# ESP32-S2 register map
Vendor: ESPRESSIF SYSTEMS (SHANGHAI) CO., LTD.; Series: ESP32 S-Series; File version: 20
CPU: Xtensa LX7 r0p0, little endian, no MPU, no FPU, 0 interrupt priority bits
Address unit: 32 bits
Registers are 32-bit, read-write, reset 0x0 unless marked. A register's access mark holds for its fields unless they carry their own. Offsets are from the block's base; [hi:lo] are bit positions; {n}, {i} and the like mark numbered series.

## SENS — SENS Peripheral
Base 0x3F408800
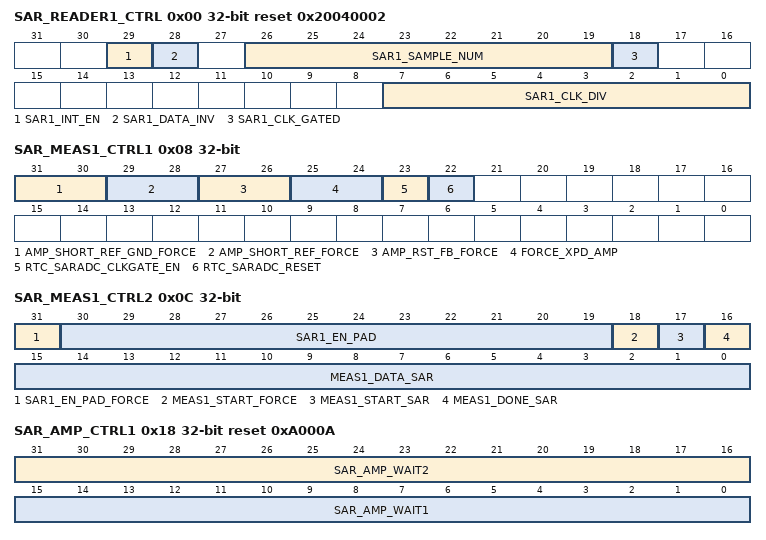
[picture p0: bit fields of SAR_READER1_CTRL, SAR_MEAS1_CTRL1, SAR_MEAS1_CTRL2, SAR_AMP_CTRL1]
0x00 SAR_READER1_CTRL reset 0x20040002 — RTC ADC1 data and sampling control
  [29] SAR1_INT_EN — Enable SAR ADC1 to send out interrupt.
  [28] SAR1_DATA_INV — Invert SAR ADC1 data.
  [26:19] SAR1_SAMPLE_NUM
  [18] SAR1_CLK_GATED
  [7:0] SAR1_CLK_DIV — Clock divider.
0x04 SAR_READER1_STATUS ro — saradc1 status for debug
  [31:0] SAR1_READER_STATUS
0x08 SAR_MEAS1_CTRL1 — Configure RTC ADC1 controller
  [31:30] AMP_SHORT_REF_GND_FORCE
  [29:28] AMP_SHORT_REF_FORCE
  [27:26] AMP_RST_FB_FORCE
  [25:24] FORCE_XPD_AMP
  [23] RTC_SARADC_CLKGATE_EN — Enable bit of SAR ADC clock gate.
  [22] RTC_SARADC_RESET — SAR ADC software reset.
0x0C SAR_MEAS1_CTRL2 access per field — Control RTC ADC1 conversion and status
  [31] SAR1_EN_PAD_FORCE rw — 1: SAR ADC1 pad enable bitmap is controlled by software. 0: SAR ADC1 pad enable bitmap is controlled by ULP coprocessor.
  [30:19] SAR1_EN_PAD rw — SAR ADC1 pad enable bitmap, active only when SENS_SAR1_EN_PAD_FORCE = 1.
  [18] MEAS1_START_FORCE rw — 1: SAR ADC1 controller (in RTC) is started by software. 0: SAR ADC1 controller is started by ULP coprocessor.
  [17] MEAS1_START_SAR rw — SAR ADC1 controller (in RTC) starts conversion, active only when SENS_MEAS1_START_FORCE = 1.
  [16] MEAS1_DONE_SAR ro — Indicate SAR ADC1 conversion is done.
  [15:0] MEAS1_DATA_SAR ro — SAR ADC1 data
0x10 SAR_MEAS1_MUX — Select the controller for SAR ADC1
  [31] SAR1_DIG_FORCE — 1: SAR ADC1 controlled by DIG ADC1 CTRL
0x14 SAR_ATTEN1 reset 0xFFFFFFFF — Configure SAR ADC1 attenuation
  [31:0] SAR1_ATTEN — 2-bit attenuation for each pad. [1:0] is used for channel 0, [3:2] is used for channel 1, etc.
0x18 SAR_AMP_CTRL1 reset 0xA000A — AMP control
  [31:16] SAR_AMP_WAIT2, [15:0] SAR_AMP_WAIT1
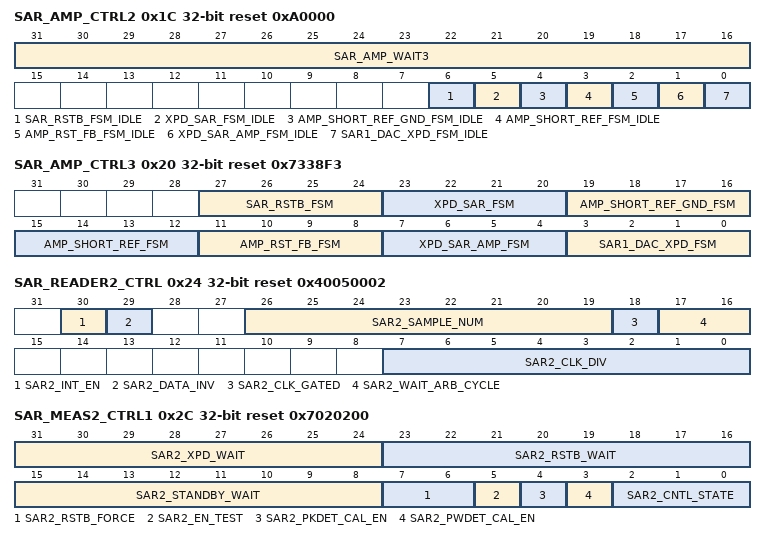
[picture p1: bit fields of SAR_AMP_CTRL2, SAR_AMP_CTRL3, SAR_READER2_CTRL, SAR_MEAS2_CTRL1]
0x1C SAR_AMP_CTRL2 reset 0xA0000 — AMP control
  [31:16] SAR_AMP_WAIT3, [6] SAR_RSTB_FSM_IDLE, [5] XPD_SAR_FSM_IDLE, [4] AMP_SHORT_REF_GND_FSM_IDLE, [3] AMP_SHORT_REF_FSM_IDLE, [2] AMP_RST_FB_FSM_IDLE, [1] XPD_SAR_AMP_FSM_IDLE, [0] SAR1_DAC_XPD_FSM_IDLE
0x20 SAR_AMP_CTRL3 reset 0x7338F3 — AMP control register
  [27:24] SAR_RSTB_FSM
  [23:20] XPD_SAR_FSM
  [19:16] AMP_SHORT_REF_GND_FSM
  [15:12] AMP_SHORT_REF_FSM
  [11:8] AMP_RST_FB_FSM
  [7:4] XPD_SAR_AMP_FSM
  [3:0] SAR1_DAC_XPD_FSM — Control of DAC. 4’b0010: disable DAC. 4’b0000: power up DAC by FSM. 4’b0011: power up DAC by software.
0x24 SAR_READER2_CTRL reset 0x40050002 — RTC ADC2 data and sampling control
  [30] SAR2_INT_EN — enable saradc2 to send out interrupt
  [29] SAR2_DATA_INV — Invert SAR ADC2 data
  [26:19] SAR2_SAMPLE_NUM
  [18] SAR2_CLK_GATED
  [17:16] SAR2_WAIT_ARB_CYCLE — wait arbit stable after sar_done
  [7:0] SAR2_CLK_DIV — clock divider
0x28 SAR_READER2_STATUS ro — saradc2 status for debug
  [31:0] SAR2_READER_STATUS
0x2C SAR_MEAS2_CTRL1 access per field reset 0x7020200 — configure rtc saradc2
  [31:24] SAR2_XPD_WAIT rw
  [23:16] SAR2_RSTB_WAIT rw
  [15:8] SAR2_STANDBY_WAIT rw
  [7:6] SAR2_RSTB_FORCE rw
  [5] SAR2_EN_TEST rw
  [4] SAR2_PKDET_CAL_EN rw — rtc control pkdet enable
  [3] SAR2_PWDET_CAL_EN rw — rtc control pwdet enable
  [2:0] SAR2_CNTL_STATE ro — saradc2_cntl_fsm
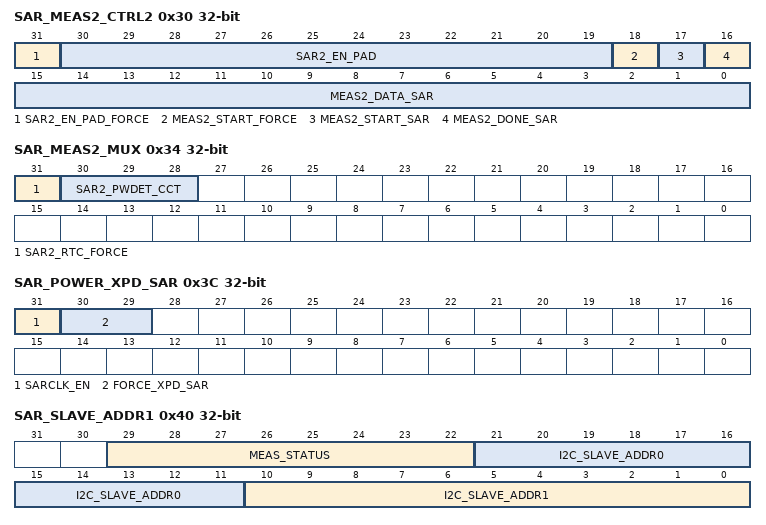
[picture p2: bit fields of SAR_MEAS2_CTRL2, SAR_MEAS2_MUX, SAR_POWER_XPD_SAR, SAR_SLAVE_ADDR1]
0x30 SAR_MEAS2_CTRL2 access per field — Control RTC ADC2 conversion and status
  [31] SAR2_EN_PAD_FORCE rw — 1: SAR ADC2 pad enable bitmap is controlled by software. 0: SAR ADC2 pad enable bitmap is controlled by ULP coprocessor.
  [30:19] SAR2_EN_PAD rw — SAR ADC2 pad enable bitmap, active only whenSENS_SAR2_EN_PAD_FORCE = 1.
  [18] MEAS2_START_FORCE rw — 1: SAR ADC2 controller (in RTC) is started by software. 0: SAR ADC2 controller is started by ULP coprocessor.
  [17] MEAS2_START_SAR rw — SAR ADC2 controller (in RTC) starts conversion, active only when SENS_MEAS2_START_FORCE = 1.
  [16] MEAS2_DONE_SAR ro — Indicate SAR ADC2 conversion is done.
  [15:0] MEAS2_DATA_SAR ro — SAR ADC2 data.
0x34 SAR_MEAS2_MUX — Select the controller for SAR ADC2
  [31] SAR2_RTC_FORCE — In sleep, force to use RTC to control ADC.
  [30:28] SAR2_PWDET_CCT — SAR2_PWDET_CCT, PA power detector capacitance tuning.
0x38 SAR_ATTEN2 reset 0xFFFFFFFF — Configure SAR ADC2 attenuation
  [31:0] SAR2_ATTEN — 2-bit attenuation for each pad. [1:0] is used for channel 0, [3:2] is used for channel 1, etc.
0x3C SAR_POWER_XPD_SAR — configure saradc’s power by sw
  [31] SARCLK_EN, [30:29] FORCE_XPD_SAR
0x40 SAR_SLAVE_ADDR1 access per field — Configure slave addresses 0-1 of RTC I2C
  [29:22] MEAS_STATUS ro
  [21:11] I2C_SLAVE_ADDR0 rw — RTC I2C slave address 0
  [10:0] I2C_SLAVE_ADDR1 rw — RTC I2C slave address 1
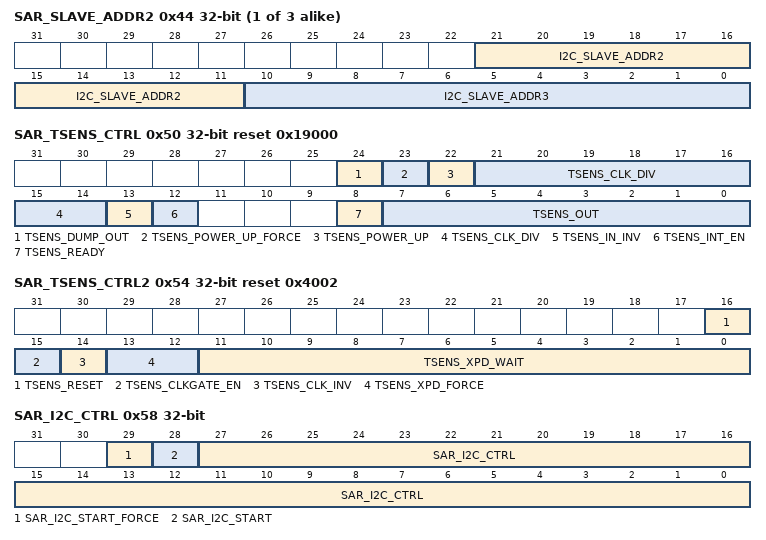
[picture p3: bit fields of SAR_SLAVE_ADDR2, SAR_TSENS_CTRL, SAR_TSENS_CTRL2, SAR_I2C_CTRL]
{0x3C+4i} SAR_SLAVE_ADDR{i} (i=2..4) — Configure slave addresses {2i-2}-{2i-1} of RTC I2C
  [21:11] I2C_SLAVE_ADDR{2i-2} — RTC I2C slave address {2i-2}
  [10:0] I2C_SLAVE_ADDR{2i-1} — RTC I2C slave address {2i-1}
0x50 SAR_TSENS_CTRL access per field reset 0x19000 — Temperature sensor data control
  [24] TSENS_DUMP_OUT rw — Temperature sensor dump out only active when SENS_TSENS_POWER_UP_FORCE = 1.
  [23] TSENS_POWER_UP_FORCE rw — 1: dump out and power up controlled by software. 0: by FSM.
  [22] TSENS_POWER_UP rw — Temperature sensor power up.
  [21:14] TSENS_CLK_DIV rw — Temperature sensor clock divider.
  [13] TSENS_IN_INV rw — Invert temperature sensor data.
  [12] TSENS_INT_EN rw — Enable temperature sensor to send out interrupt.
  [8] TSENS_READY ro — Indicate temperature sensor out ready.
  [7:0] TSENS_OUT ro — Temperature sensor data out.
0x54 SAR_TSENS_CTRL2 reset 0x4002 — Temperature sensor control
  [16] TSENS_RESET — Reset temperature sensor.
  [15] TSENS_CLKGATE_EN — Enable temperature sensor clock.
  [14] TSENS_CLK_INV
  [13:12] TSENS_XPD_FORCE
  [11:0] TSENS_XPD_WAIT
0x58 SAR_I2C_CTRL — Configure RTC I2C transmission
  [29] SAR_I2C_START_FORCE — 0: RTC I2C started by FSM. 1: RTC I2C started by software.
  [28] SAR_I2C_START — Start RTC I2C. Active only when SENS_SAR_I2C_START_FORCE = 1
  [27:0] SAR_I2C_CTRL — RTC I2C control data. Active only when SENS_SAR_I2C_START_FORCE = 1.
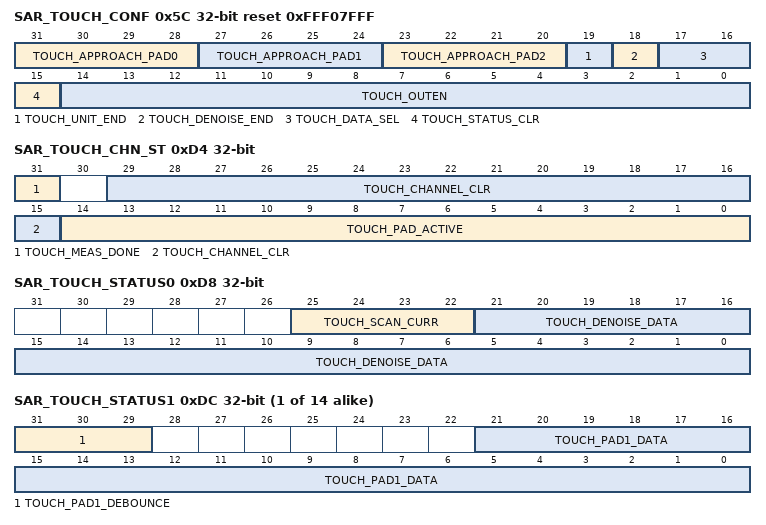
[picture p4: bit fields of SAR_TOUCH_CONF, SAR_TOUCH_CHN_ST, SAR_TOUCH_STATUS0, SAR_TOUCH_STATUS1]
0x5C SAR_TOUCH_CONF access per field reset 0xFFF07FFF — Touch sensor configuration register
  [31:28] TOUCH_APPROACH_PAD0 rw — Indicate which pad is selected as proximity pad0
  [27:24] TOUCH_APPROACH_PAD1 rw — Indicate which pad is selected as proximity pad1
  [23:20] TOUCH_APPROACH_PAD2 rw — Indicate which pad is selected as proximity pad2
  [19] TOUCH_UNIT_END ro — Indicate the completion of sampling.
  [18] TOUCH_DENOISE_END ro — Touch denoise done.
  [17:16] TOUCH_DATA_SEL rw — 0 and 1: touch_raw_data; 2: base_line; 3: touch_smooth_data.
  [15] TOUCH_STATUS_CLR wo — Clear all touch active status.
  [14:0] TOUCH_OUTEN rw — Enable touch controller output.
{0x5C+4i} SAR_TOUCH_THRES{i} (i=1..14) — Finger threshold for touch pad {i}
  [21:0] TOUCH_OUT_TH{i}
0xD4 SAR_TOUCH_CHN_ST access per field — Touch channel status register
  [31] TOUCH_MEAS_DONE ro — Signal flag that indicates one touch pad is done.
  [29:15] TOUCH_CHANNEL_CLR wo — Clear touch channel
  [14:0] TOUCH_PAD_ACTIVE ro — Touch active status
0xD8 SAR_TOUCH_STATUS0 ro — Status of touch controller
  [25:22] TOUCH_SCAN_CURR — Current pad in scan status
  [21:0] TOUCH_DENOISE_DATA — Denoise measure value from touch sensor 0.
{0xD8+4i} SAR_TOUCH_STATUS{i} ro (i=1..14) — Touch pad {i} status
  [31:29] TOUCH_PAD{i}_DEBOUNCE — Touch pad {i} debounce value.
  [21:0] TOUCH_PAD{i}_DATA — The data of touch pad {i}, depending on the setting of SENS_TOUCH_DATA_SEL.
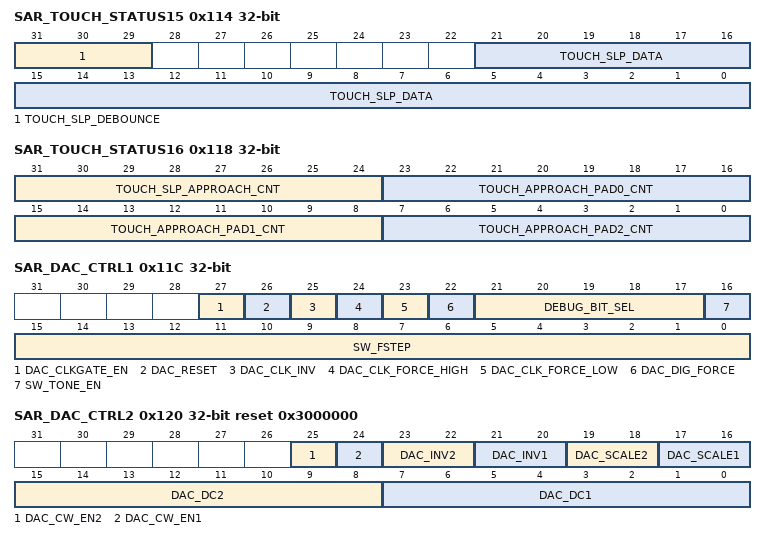
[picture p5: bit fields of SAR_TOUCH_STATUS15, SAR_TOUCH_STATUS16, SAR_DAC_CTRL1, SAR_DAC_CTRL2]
0x114 SAR_TOUCH_STATUS15 ro — Touch sleep pad status
  [31:29] TOUCH_SLP_DEBOUNCE — Touch sleep pad debouce value.
  [21:0] TOUCH_SLP_DATA — The data of touch sleep pad, depending on the setting of SENS_TOUCH_DATA_SEL.
0x118 SAR_TOUCH_STATUS16 ro — Touch approach count status
  [31:24] TOUCH_SLP_APPROACH_CNT — Count status of sleep pad in proximity mode.
  [23:16] TOUCH_APPROACH_PAD0_CNT — Count status of proximity pad 0.
  [15:8] TOUCH_APPROACH_PAD1_CNT — Count status of proximity pad 1.
  [7:0] TOUCH_APPROACH_PAD2_CNT — Count status of proximity pad 2.
0x11C SAR_DAC_CTRL1 — DAC control
  [27] DAC_CLKGATE_EN — DAC clock gate enable bit.
  [26] DAC_RESET — Reset DAC by software.
  [25] DAC_CLK_INV — 1: invert PDAC_CLK.
  [24] DAC_CLK_FORCE_HIGH — 1: force PDAC_CLK to high
  [23] DAC_CLK_FORCE_LOW — 1: force PDAC_CLK to low
  [22] DAC_DIG_FORCE — 0: DAC1 and DAC2 do not use DMA. 1: DAC1 and DAC2 use DMA.
  [21:17] DEBUG_BIT_SEL
  [16] SW_TONE_EN — 0: disable CW generator. 1: enable CW generator.
  [15:0] SW_FSTEP — Frequency step for CW generator can be used to adjust the frequency.
0x120 SAR_DAC_CTRL2 reset 0x3000000 — DAC output control
  [25] DAC_CW_EN2 — 1: select CW generator as source for PDAC2_DAC. 0: select register RT- CIO_PDAC2_DAC as source for PDAC2_DAC.
  [24] DAC_CW_EN1 — 1: select CW generator as source for PDAC1_DAC. 0: select register RT- CIO_PDAC1_DAC as source for PDAC1_DAC.
  [23:22] DAC_INV2 — Invert DAC2. 00: do not invert any bits. 01: invert all bits. 10: invert MSB. 11: invert all bits except MSB.
  [21:20] DAC_INV1 — Invert DAC1. 00: do not invert any bits. 01: invert all bits. 10: invert MSB. 11: invert all bits except MSB.
  [19:18] DAC_SCALE2 — DAC2 scaling. 00: no scale. 01: scale to 1/2. 10: scale to 1/4. 11: scale to 1/8.
  [17:16] DAC_SCALE1 — DAC1 scaling. 00: no scale. 01: scale to 1/2. 10: scale to 1/4. 11: scale to 1/8.
  [15:8] DAC_DC2 — DC offset for DAC2 CW generator.
  [7:0] DAC_DC1 — DC offset for DAC1 CW generator.
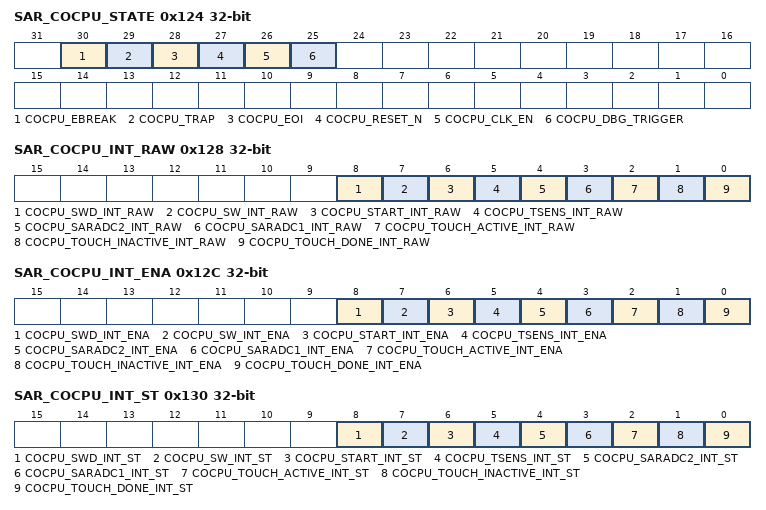
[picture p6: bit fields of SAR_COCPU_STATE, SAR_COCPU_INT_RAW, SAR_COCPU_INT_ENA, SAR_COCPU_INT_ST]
0x124 SAR_COCPU_STATE access per field — ULP-RISCV status
  [30] COCPU_EBREAK ro — Check ULP-RISCV whether in ebreak
  [29] COCPU_TRAP ro — Check ULP-RISCV whether in trap state
  [28] COCPU_EOI ro — Check ULP-RISCV whether in interrupt state
  [27] COCPU_RESET_N ro — Check ULP-RISCV whether in reset state
  [26] COCPU_CLK_EN ro — Check ULP-RISCV whether clk on
  [25] COCPU_DBG_TRIGGER wo — Trigger ULP-RISCV debug registers
0x128 SAR_COCPU_INT_RAW ro — Interrupt raw bit of ULP-RISCV
  [8] COCPU_SWD_INT_RAW — SWD_INT interrupt raw bit
  [7] COCPU_SW_INT_RAW — SW_INT interrupt raw bit
  [6] COCPU_START_INT_RAW — RISCV_START_INT interrupt raw bit
  [5] COCPU_TSENS_INT_RAW — TSENS_DONE_INT interrupt raw bit
  [4] COCPU_SARADC2_INT_RAW — SARADC2_DONE_INT interrupt raw bit
  [3] COCPU_SARADC1_INT_RAW — SARADC1_DONE_INT interrupt raw bit
  [2] COCPU_TOUCH_ACTIVE_INT_RAW — TOUCH_ACTIVE_INT interrupt raw bit
  [1] COCPU_TOUCH_INACTIVE_INT_RAW — TOUCH_INACTIVE_INT interrupt raw bit
  [0] COCPU_TOUCH_DONE_INT_RAW — TOUCH_DONE_INT interrupt raw bit
0x12C SAR_COCPU_INT_ENA — Interrupt enable bit of ULP-RISCV
  [8] COCPU_SWD_INT_ENA — SWD_INT interrupt enable bit
  [7] COCPU_SW_INT_ENA — SW_INT interrupt enable bit
  [6] COCPU_START_INT_ENA — RISCV_START_INT interrupt enable bit
  [5] COCPU_TSENS_INT_ENA — TSENS_DONE_INT interrupt enable bit
  [4] COCPU_SARADC2_INT_ENA — SARADC2_DONE_INT interrupt enable bit
  [3] COCPU_SARADC1_INT_ENA — SARADC1_DONE_INT interrupt enable bit
  [2] COCPU_TOUCH_ACTIVE_INT_ENA — TOUCH_ACTIVE_INT interrupt enable bit
  [1] COCPU_TOUCH_INACTIVE_INT_ENA — TOUCH_INACTIVE_INT interrupt enable bit
  [0] COCPU_TOUCH_DONE_INT_ENA — TOUCH_DONE_INT interrupt enable bit
0x130 SAR_COCPU_INT_ST ro — Interrupt status bit of ULP-RISCV
  [8] COCPU_SWD_INT_ST — SWD_INT interrupt status bit
  [7] COCPU_SW_INT_ST — SW_INT interrupt status bit
  [6] COCPU_START_INT_ST — RISCV_START_INT interrupt status bit
  [5] COCPU_TSENS_INT_ST — TSENS_DONE_INT interrupt status bit
  [4] COCPU_SARADC2_INT_ST — SARADC2_DONE_INT interrupt status bit
  [3] COCPU_SARADC1_INT_ST — SARADC1_DONE_INT interrupt status bit
  [2] COCPU_TOUCH_ACTIVE_INT_ST — TOUCH_ACTIVE_INT interrupt status bit
  [1] COCPU_TOUCH_INACTIVE_INT_ST — TOUCH_INACTIVE_INT interrupt status bit
  [0] COCPU_TOUCH_DONE_INT_ST — TOUCH_DONE_INT interrupt status bit
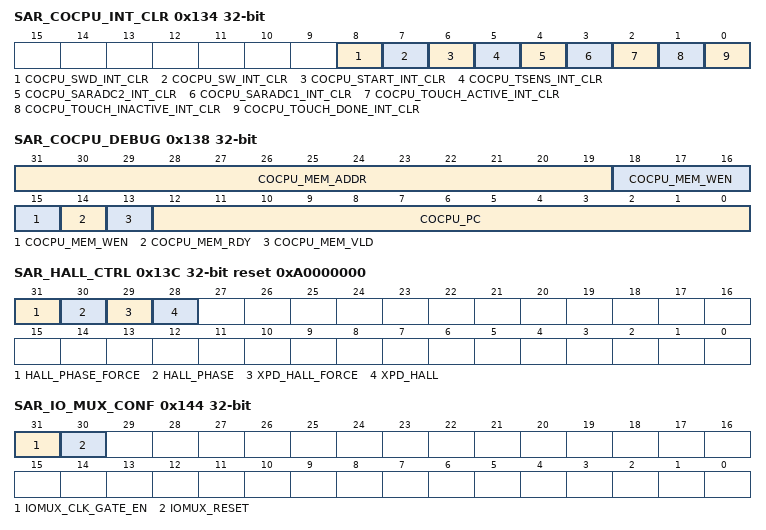
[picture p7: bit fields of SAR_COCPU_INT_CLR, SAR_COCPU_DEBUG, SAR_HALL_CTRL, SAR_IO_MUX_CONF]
0x134 SAR_COCPU_INT_CLR wo — Interrupt clear bit of ULP-RISCV
  [8] COCPU_SWD_INT_CLR — SWD_INT interrupt clear bit
  [7] COCPU_SW_INT_CLR — SW_INT interrupt clear bit
  [6] COCPU_START_INT_CLR — RISCV_START_INT interrupt clear bit
  [5] COCPU_TSENS_INT_CLR — TSENS_DONE_INT interrupt clear bit
  [4] COCPU_SARADC2_INT_CLR — SARADC2_DONE_INT interrupt clear bit
  [3] COCPU_SARADC1_INT_CLR — SARADC1_DONE_INT interrupt clear bit
  [2] COCPU_TOUCH_ACTIVE_INT_CLR — TOUCH_ACTIVE_INT interrupt clear bit
  [1] COCPU_TOUCH_INACTIVE_INT_CLR — TOUCH_INACTIVE_INT interrupt clear bit
  [0] COCPU_TOUCH_DONE_INT_CLR — TOUCH_DONE_INT interrupt clear bit
0x138 SAR_COCPU_DEBUG ro — ULP-RISCV debug register
  [31:19] COCPU_MEM_ADDR — ULP-RISCV memory address output
  [18:15] COCPU_MEM_WEN — ULP-RISCV memory write enable output
  [14] COCPU_MEM_RDY — ULP-RISCV memory ready input
  [13] COCPU_MEM_VLD — ULP-RISCV memory valid output
  [12:0] COCPU_PC — ULP-RISCV Program counter
0x13C SAR_HALL_CTRL reset 0xA0000000 — hall control
  [31] HALL_PHASE_FORCE — 1: HALL PHASE is controlled by SW 0: HALL PHASE is controlled by FSM in ULP-coprocessor
  [30] HALL_PHASE — Reverse phase of hall sensor
  [29] XPD_HALL_FORCE — 1: XPD HALL is controlled by SW. 0: XPD HALL is controlled by FSM in ULP-coprocessor
  [28] XPD_HALL — Power on hall sensor and connect to VP and VN
0x140 SAR_NOUSE
0x144 SAR_IO_MUX_CONF — Configure and reset IO MUX
  [31] IOMUX_CLK_GATE_EN — IO MUX clock gate enable bit
  [30] IOMUX_RESET — Reset IO MUX by software
0x148 SARDATE reset 0x1906140 — Version Control Register
  [27:0] SAR_DATE
